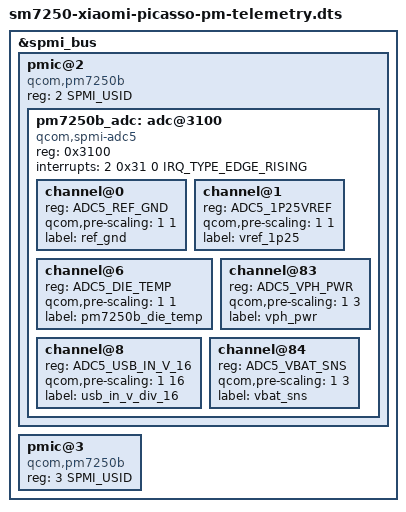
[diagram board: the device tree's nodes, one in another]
// SPDX-License-Identifier: BSD-3-Clause
/* Opt-in observational PM7250B support for Picasso. No charger, Type-C,
 * vbus regulator, fuel-gauge writes, or suspend policy changes.
 * ADC definitions derived from Linux qcom/pm7250b.dtsi:
 * Copyright (C) 2022 Luca Weiss <luca.weiss@fairphone.com>.
 * SID 2 / ADC base 0x3100 and channels are cross-checked against ROM DTB9+DTBO19.
 */
#include "sm7250-xiaomi-picasso-fedora.dts"
#include <dt-bindings/iio/qcom,spmi-vadc.h>
#include <dt-bindings/interrupt-controller/irq.h>
#include <dt-bindings/spmi/spmi.h>

&spmi_bus {
	pmic@2 {
		compatible = "qcom,pm7250b", "qcom,spmi-pmic";
		reg = <2 SPMI_USID>;
		#address-cells = <1>;
		#size-cells = <0>;

		pm7250b_adc: adc@3100 {
			compatible = "qcom,spmi-adc5";
			reg = <0x3100>;
			#address-cells = <1>;
			#size-cells = <0>;
			#io-channel-cells = <1>;
			interrupts = <2 0x31 0 IRQ_TYPE_EDGE_RISING>;

			channel@0 {
				reg = <ADC5_REF_GND>;
				qcom,pre-scaling = <1 1>;
				label = "ref_gnd";
			};
			channel@1 {
				reg = <ADC5_1P25VREF>;
				qcom,pre-scaling = <1 1>;
				label = "vref_1p25";
			};
			channel@6 {
				reg = <ADC5_DIE_TEMP>;
				qcom,pre-scaling = <1 1>;
				label = "pm7250b_die_temp";
			};
			channel@8 {
				reg = <ADC5_USB_IN_V_16>;
				qcom,pre-scaling = <1 16>;
				label = "usb_in_v_div_16";
			};
			channel@83 {
				reg = <ADC5_VPH_PWR>;
				qcom,pre-scaling = <1 3>;
				label = "vph_pwr";
			};
			/* This channel exists in upstream PM7250B; do not derive a
			 * battery percentage from it or silently substitute VPH. */
			channel@84 {
				reg = <ADC5_VBAT_SNS>;
				qcom,pre-scaling = <1 3>;
				label = "vbat_sns";
			};
		};
	};

	pmic@3 {
		compatible = "qcom,pm7250b", "qcom,spmi-pmic";
		reg = <3 SPMI_USID>;
		#address-cells = <1>;
		#size-cells = <0>;
	};
};
